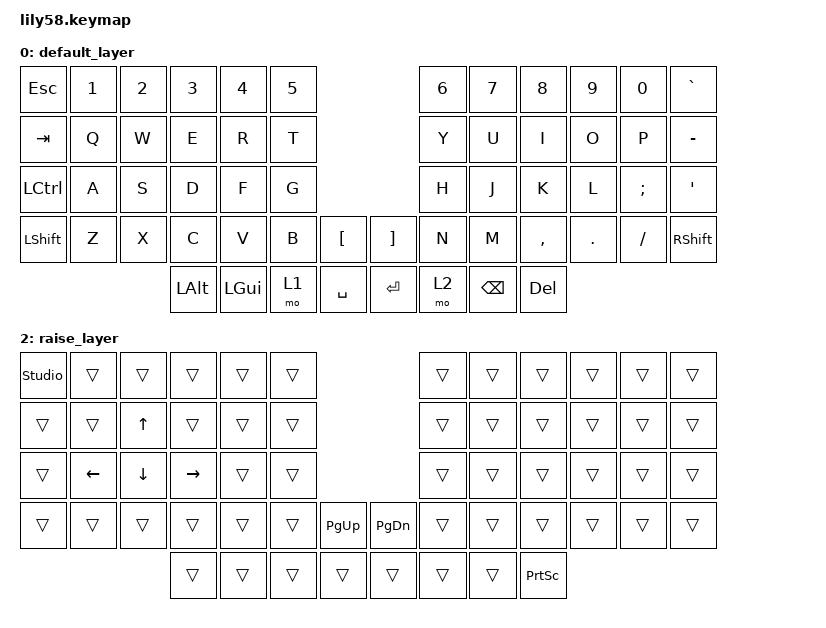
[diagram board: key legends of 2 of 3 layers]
/*
 * Copyright (c) 2020 The ZMK Contributors
 *
 * SPDX-License-Identifier: MIT
 */

#include <behaviors.dtsi>
#include <dt-bindings/zmk/keys.h>
#include <dt-bindings/zmk/bt.h>
#include <dt-bindings/zmk/ext_power.h>

/ {
    keymap {
        compatible = "zmk,keymap";

        default_layer {
// ------------------------------------------------------------------------------------------------------------
// |  ESC  |  1  |  2  |  3   |  4   |  5   |                   |  6   |  7    |  8    |  9   |   0   |   `   |
// |  TAB  |  Q  |  W  |  E   |  R   |  T   |                   |  Y   |  U    |  I    |  O   |   P   |   -   |
// |  CTRL |  A  |  S  |  D   |  F   |  G   |                   |  H   |  J    |  K    |  L   |   ;   |   '   |
// | SHIFT |  Z  |  X  |  C   |  V   |  B   |   "["  |  |  "]"  |  N   |  M    |  ,    |  .   |   /   | SHIFT |
//                     | ALT  | GUI  | LOWER|  SPACE |  | ENTER | RAISE| BSPC  | DEL   |
            bindings = <
&kp ESC   &kp N1 &kp N2 &kp N3   &kp N4   &kp N5                     &kp N6 &kp N7   &kp N8    &kp N9  &kp N0   &kp GRAVE
&kp TAB   &kp Q  &kp W  &kp E    &kp R    &kp T                      &kp Y  &kp U    &kp I     &kp O   &kp P    &kp MINUS
&kp LCTRL &kp A  &kp S  &kp D    &kp F    &kp G                      &kp H  &kp J    &kp K     &kp L   &kp SEMI &kp SQT
&kp LSHFT &kp Z  &kp X  &kp C    &kp V    &kp B  &kp LBKT   &kp RBKT &kp N  &kp M    &kp COMMA &kp DOT &kp FSLH &kp RSHFT
                        &kp LALT &kp LGUI &mo 1  &kp SPACE  &kp RET  &mo 2  &kp BSPC &kp DEL
            >;

            sensor-bindings = <&inc_dec_kp C_VOL_UP C_VOL_DN>;
        };

        lower_layer {
// ------------------------------------------------------------------------------------------------------------
// |   ~   |  !  |  @  |  #   |  $   |   %  |                   |  ^   |  &    |  *    |  (   |   )   |  F13  |
// |  F1   |  F2 |  F3 |  F4  |  F5  |  F6  |                   |  F7  |  F8   |  F9   |  F10 |  F11  |  F12  |
// |       |     |     |      |      |      |                   |      |       |       |  <   |   >   |   \    |
// |       |     |     |      |      |      |  HOME  |  |  END  |      |  _    |  +    |  {   |   }   |  "|"  |
//                     |      |      |      |        |  |       |      |       |       |
            bindings = <
&kp TILDE  &kp EXCL     &kp AT      &kp HASH      &kp DOLLAR   &kp PRCNT                      &kp CARET &kp AMPS  &kp KP_MULTIPLY &kp LPAR  &kp RPAR  &kp F13
&kp F1     &kp F2       &kp F3      &kp F4        &kp F5       &kp F6                         &kp F7    &kp F8    &kp F9          &kp F10   &kp F11   &kp F12
&trans     &trans       &trans      &trans        &trans       &trans                         &trans    &trans    &trans          &kp GT    &kp LT    &kp BSLH
&trans     &trans       &trans      &trans        &trans       &trans     &kp HOME  &kp END   &kp MINUS &kp KP_PLUS     &kp LBRC  &kp RBRC  &kp PIPE
                                    &trans        &trans       &trans     &trans    &trans    &trans    &trans    &trans
            >;

            sensor-bindings = <&inc_dec_kp C_VOL_UP C_VOL_DN>;
        };

        raise_layer {
// ------------------------------------------------------------------------------------------------------------
// |   ZMKS  |     |     |      |      |      |                   |     |     |      |     |     |      |
// |     |     |  ^  |      |      |      |                   |     |     |      |     |     |      |
// |     |  <- |  v  |  ->  |      |      |                   |     |     |      |     |     |      |
// |     |     |     |      |      |      | PG_UP |   | PG_DN |     |     |      |     |     |      |
//                   |      |      |      |       |   |       |     |     | PSCRN |
            bindings = <
&studio_unlock    &trans   &trans   &trans     &trans  &trans                            &trans      &trans    &trans    &trans   &trans    &trans
&trans    &trans   &kp UP   &trans     &trans  &trans                            &trans      &trans    &trans    &trans   &trans    &trans
&trans    &kp LEFT &kp DOWN &kp RIGHT  &trans  &trans                            &trans      &trans    &trans    &trans   &trans    &trans
&trans    &trans   &trans   &trans     &trans  &trans    &kp PG_UP   &kp PG_DN   &trans      &trans    &trans    &trans   &trans    &trans
                            &trans     &trans  &trans    &trans      &trans      &trans      &trans    &kp PSCRN
            >;

            sensor-bindings = <&inc_dec_kp C_VOL_UP C_VOL_DN>;
        };
    };
};
